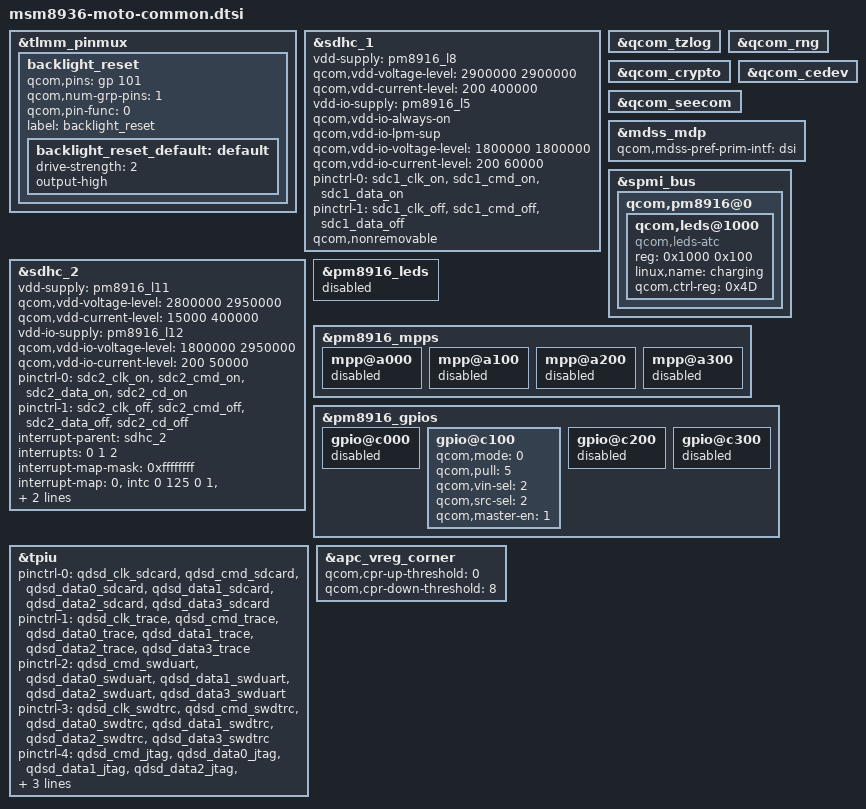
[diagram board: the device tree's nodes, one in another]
/* Copyright (c) 2014, Motorola Mobility LLC. All rights reserved.
*
* This program is free software; you can redistribute it and/or modify
* it under the terms of the GNU General Public License version 2 and
* only version 2 as published by the Free Software Foundation.
*
* This program is distributed in the hope that it will be useful,
* but WITHOUT ANY WARRANTY; without even the implied warranty of
* MERCHANTABILITY or FITNESS FOR A PARTICULAR PURPOSE.  See the
* GNU General Public License for more details.
*/

#include "msm8936.dtsi"
#include "msm8939-pinctrl.dtsi"
#include "carrier-channel-ids.dtsi"

&tlmm_pinmux {
                backlight_reset {
                        qcom,pins = <&gp 101>;
                        qcom,num-grp-pins = <1>;
                        qcom,pin-func = <0>;
                        label = "backlight_reset";
                        backlight_reset_default: default {
                                drive-strength = <2>;
                                output-high;
                        };
                };
};

&sdhc_1 {
	vdd-supply = <&pm8916_l8>;
	qcom,vdd-voltage-level = <2900000 2900000>;
	qcom,vdd-current-level = <200 400000>;

	vdd-io-supply = <&pm8916_l5>;
	qcom,vdd-io-always-on;
	qcom,vdd-io-lpm-sup;
	qcom,vdd-io-voltage-level = <1800000 1800000>;
	qcom,vdd-io-current-level = <200 60000>;

	pinctrl-names = "active", "sleep";
	pinctrl-0 = <&sdc1_clk_on &sdc1_cmd_on &sdc1_data_on>;
	pinctrl-1 = <&sdc1_clk_off &sdc1_cmd_off &sdc1_data_off>;

	qcom,nonremovable;

	status = "ok";
};

&sdhc_2 {
	vdd-supply = <&pm8916_l11>;
	qcom,vdd-voltage-level = <2800000 2950000>;
	qcom,vdd-current-level = <15000 400000>;

	vdd-io-supply = <&pm8916_l12>;
	qcom,vdd-io-voltage-level = <1800000 2950000>;
	qcom,vdd-io-current-level = <200 50000>;

	pinctrl-names = "active", "sleep";
	pinctrl-0 = <&sdc2_clk_on &sdc2_cmd_on &sdc2_data_on &sdc2_cd_on>;
	pinctrl-1 = <&sdc2_clk_off &sdc2_cmd_off &sdc2_data_off &sdc2_cd_off>;

	#address-cells = <0>;
	interrupt-parent = <&sdhc_2>;
	interrupts = <0 1 2>;
	#interrupt-cells = <1>;
	interrupt-map-mask = <0xffffffff>;
	interrupt-map = <0 &intc 0 125 0
			1 &intc 0 221 0
			2 &msm_gpio 25 0>;
	interrupt-names = "hc_irq", "pwr_irq", "status_irq";
	cd-gpios = <&msm_gpio 25 0x1>;

	status = "ok";
};

&qcom_tzlog {
	status = "okay";
};

&qcom_rng {
	status = "okay";
};

&qcom_crypto {
	status = "okay";
};

&qcom_cedev {
	status = "okay";
};

&qcom_seecom {
	status = "okay";
};

&mdss_mdp {
	qcom,mdss-pref-prim-intf = "dsi";
};

&spmi_bus {
	qcom,pm8916@0 {
		qcom,leds@1000 {
			reg = <0x1000 0x100>;
			compatible = "qcom,leds-atc";
			linux,name = "charging";
			qcom,ctrl-reg = <0x4D>;
		};
	};
};

&pm8916_leds {
	status = "disabled";
};

&pm8916_mpps {
	mpp@a000 { /* MPP 1 */
		status = "disabled";
	};

	mpp@a100 { /* MPP 2 */
		status = "disabled";
	};

	mpp@a200 { /* MPP 3 */
		status = "disabled";
	};

	mpp@a300 { /* MPP 4 */
		status = "disabled";
	};
};

&pm8916_gpios {
	gpio@c000 { /* GPIO 1 */
		/* Battery UICC Alarm */
		status = "disabled";
	};

	gpio@c100 { /* GPIO 2 */
		/* NFC_CLK_REQ */
		qcom,mode = <0>; /* QPNP_PIN_MODE_DIG_IN */
		qcom,pull = <5>; /* QPNP_PIN_PULL_NO */
		qcom,vin-sel = <2>; /* QPNP_PIN_VIN2 */
		qcom,src-sel = <2>; /* QPNP_PIN_SEL_FUNC_1 */
		qcom,master-en = <1>;
	};

	gpio@c200 { /* GPIO 3 */
		/* External regulator control for WTR */
		status = "disabled";
	};

	gpio@c300 { /* GPIO 4 */
		/* External regulator control for APC */
		status = "disabled";
	};
};

/* CoreSight */
&tpiu {
	pinctrl-names = "sdcard", "trace", "swduart",
			"swdtrc", "jtag", "spmi";
	/* NIDnT */
	pinctrl-0 = <&qdsd_clk_sdcard &qdsd_cmd_sdcard
		     &qdsd_data0_sdcard &qdsd_data1_sdcard
		     &qdsd_data2_sdcard &qdsd_data3_sdcard>;
	pinctrl-1 = <&qdsd_clk_trace &qdsd_cmd_trace
		     &qdsd_data0_trace &qdsd_data1_trace
		     &qdsd_data2_trace &qdsd_data3_trace>;
	pinctrl-2 = <&qdsd_cmd_swduart &qdsd_data0_swduart
		     &qdsd_data1_swduart &qdsd_data2_swduart
		     &qdsd_data3_swduart>;
	pinctrl-3 = <&qdsd_clk_swdtrc &qdsd_cmd_swdtrc
		     &qdsd_data0_swdtrc &qdsd_data1_swdtrc
		     &qdsd_data2_swdtrc &qdsd_data3_swdtrc>;
	pinctrl-4 = <&qdsd_cmd_jtag &qdsd_data0_jtag
		     &qdsd_data1_jtag &qdsd_data2_jtag
		     &qdsd_data3_jtag>;
	pinctrl-5 = <&qdsd_clk_spmi &qdsd_cmd_spmi
		     &qdsd_data0_spmi &qdsd_data3_spmi>;
};

&apc_vreg_corner {
		qcom,cpr-up-threshold = <0>;
		qcom,cpr-down-threshold = <8>;
};
